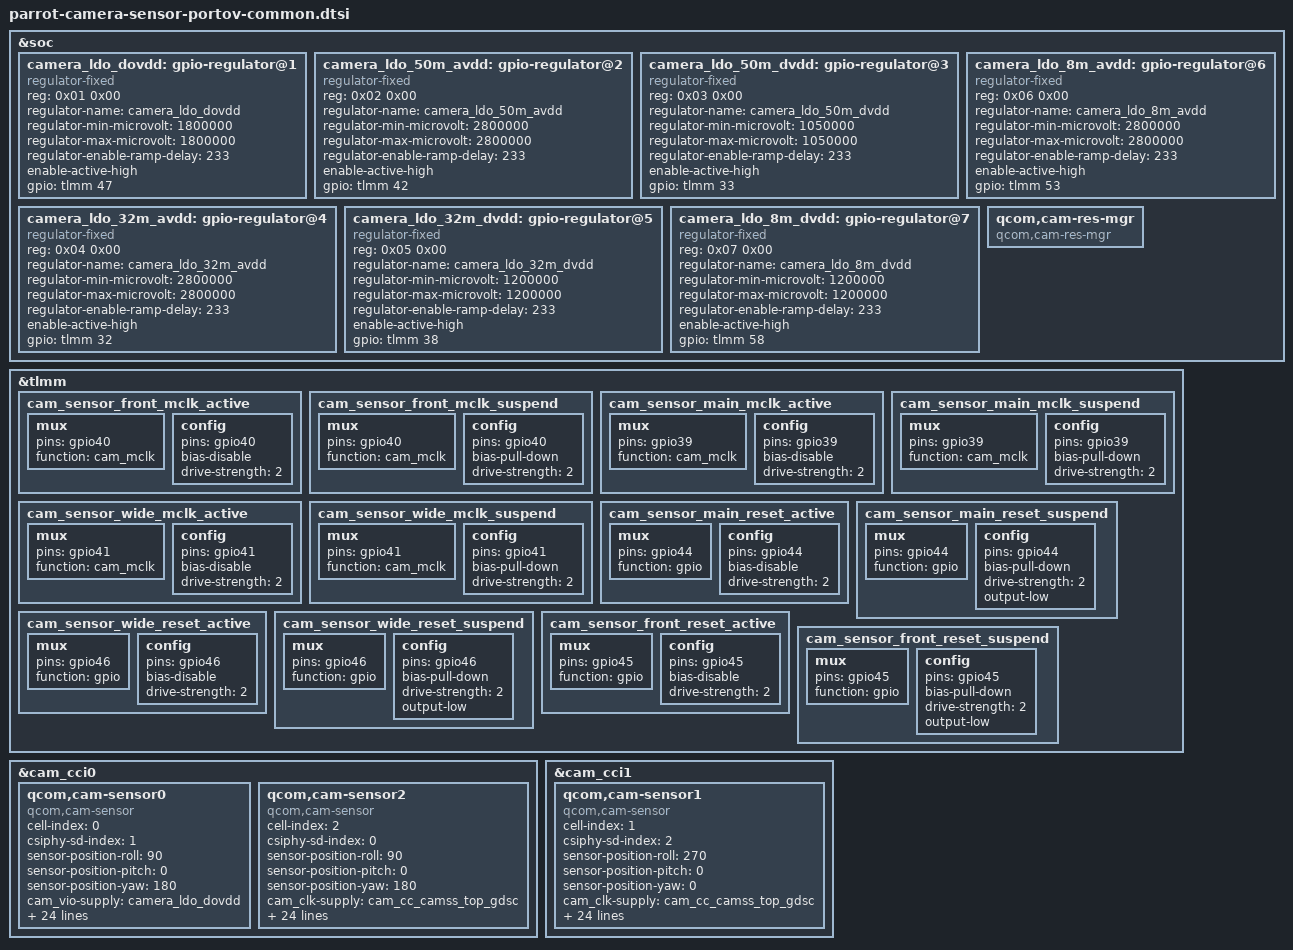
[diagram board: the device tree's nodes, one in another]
/*
   This base is original from "cape-camera-sensor-bronco-common.dtsi"
*/
#include <dt-bindings/clock/qcom,camcc-parrot.h>
#include <dt-bindings/msm-camera.h>

&soc {
	/* imx882 afvdd */
	/*camera_ldo_50m_afvdd: gpio-regulator@0 {
		compatible = "regulator-fixed";
		reg = <0x00 0x00>;
		regulator-name = "camera_ldo_50m_afvdd";
		regulator-min-microvolt = <2800000>;
		regulator-max-microvolt = <2800000>;
		regulator-enable-ramp-delay = <233>;
		enable-active-high;
		gpio = <&tlmm 31 0>;
	};*/

	camera_ldo_dovdd: gpio-regulator@1 {
		compatible = "regulator-fixed";
		reg = <0x01 0x00>;
		regulator-name = "camera_ldo_dovdd";
		regulator-min-microvolt = <1800000>;
		regulator-max-microvolt = <1800000>;
		regulator-enable-ramp-delay = <233>;
		enable-active-high;
		gpio = <&tlmm 47 0>;
	};

	/* imx882 avdd */
	camera_ldo_50m_avdd: gpio-regulator@2 {
		compatible = "regulator-fixed";
		reg = <0x02 0x00>;
		regulator-name = "camera_ldo_50m_avdd";
		regulator-min-microvolt = <2800000>;
		regulator-max-microvolt = <2800000>;
		regulator-enable-ramp-delay = <233>;
		enable-active-high;
		gpio = <&tlmm 42 0>;
	};
	/* imx882 dvdd */
	camera_ldo_50m_dvdd: gpio-regulator@3 {
		compatible = "regulator-fixed";
		reg = <0x03 0x00>;
		regulator-name = "camera_ldo_50m_dvdd";
		regulator-min-microvolt = <1050000>;
		regulator-max-microvolt = <1050000>;
		regulator-enable-ramp-delay = <233>;
		enable-active-high;
		gpio = <&tlmm 33 0>;
	};
	/* gc32e1 avdd */
	camera_ldo_32m_avdd: gpio-regulator@4 {
		compatible = "regulator-fixed";
		reg = <0x04 0x00>;
		regulator-name = "camera_ldo_32m_avdd";
		regulator-min-microvolt = <2800000>;
		regulator-max-microvolt = <2800000>;
		regulator-enable-ramp-delay = <233>;
		enable-active-high;
		gpio = <&tlmm 32 0>;
	};
	/* gc32e1 dvdd */
	camera_ldo_32m_dvdd: gpio-regulator@5 {
		compatible = "regulator-fixed";
		reg = <0x05 0x00>;
		regulator-name = "camera_ldo_32m_dvdd";
		regulator-min-microvolt = <1200000>;
		regulator-max-microvolt = <1200000>;
		regulator-enable-ramp-delay = <233>;
		enable-active-high;
		gpio = <&tlmm 38 0>;
	};
	/* sc820cs/gc08a8 avdd */
	camera_ldo_8m_avdd: gpio-regulator@6 {
		compatible = "regulator-fixed";
		reg = <0x06 0x00>;
		regulator-name = "camera_ldo_8m_avdd";
		regulator-min-microvolt = <2800000>;
		regulator-max-microvolt = <2800000>;
		regulator-enable-ramp-delay = <233>;
		enable-active-high;
		gpio = <&tlmm 53 0>;
	};
	/* sc820cs/gc08a8 dvdd */
	camera_ldo_8m_dvdd: gpio-regulator@7 {
		compatible = "regulator-fixed";
		reg = <0x07 0x00>;
		regulator-name = "camera_ldo_8m_dvdd";
		regulator-min-microvolt = <1200000>;
		regulator-max-microvolt = <1200000>;
		regulator-enable-ramp-delay = <233>;
		enable-active-high;
		gpio = <&tlmm 58 0>;
	};

        /*led_flash_rear: qcom,camera-flash@1 {
		cell-index = <1>;
		compatible = "qcom,camera-flash";
		flash-source = <&pm6150l_flash0 &pm6150l_flash1>;
		torch-source = <&pm6150l_torch0 &pm6150l_torch1>;
		switch-source = <&pm6150l_switch2>;
		status = "ok";
	};*/

	qcom,cam-res-mgr {
		compatible = "qcom,cam-res-mgr";
		status = "ok";
	};
};

&tlmm {
        cam_sensor_front_mclk_active: cam_sensor_front_mclk_active {
		mux {
			pins = "gpio40";
			function = "cam_mclk";
		};

		config {
			pins = "gpio40";
			bias-disable;
			drive-strength = <2>;
		};
	};

	cam_sensor_front_mclk_suspend: cam_sensor_front_mclk_suspend {
		mux {
			pins = "gpio40";
			function = "cam_mclk";
		};

		config {
			pins = "gpio40";
			bias-pull-down;
			drive-strength = <2>;
		};
	};

	cam_sensor_main_mclk_active: cam_sensor_main_mclk_active {
		mux {
			pins = "gpio39";
			function = "cam_mclk";
		};

		config {
			pins = "gpio39";
			bias-disable; /* No PULL */
			drive-strength = <2>; /* 2 MA */
		};
	};

	cam_sensor_main_mclk_suspend: cam_sensor_main_mclk_suspend {
		mux {
			pins = "gpio39";
			function = "cam_mclk";
		};

		config {
			pins = "gpio39";
			bias-pull-down; /* PULL DOWN */
			drive-strength = <2>; /* 2 MA */
		};
	};

	cam_sensor_wide_mclk_active: cam_sensor_wide_mclk_active {
		mux {
			pins = "gpio41";
			function = "cam_mclk";
		};

		config {
			pins = "gpio41";
			bias-disable; /* No PULL */
			drive-strength = <2>;
		};
	};

	cam_sensor_wide_mclk_suspend: cam_sensor_wide_mclk_suspend {
		mux {
			pins = "gpio41";
			function = "cam_mclk";
		};

		config {
			pins = "gpio41";
			bias-pull-down; /* PULL DOWN */
			drive-strength = <2>;
		};
	};
	cam_sensor_main_reset_active: cam_sensor_main_reset_active {
		mux {
			pins = "gpio44";
			function = "gpio";
		};

		config {
			pins = "gpio44";
			bias-disable; /* No PULL */
			drive-strength = <2>; /* 2 MA */
		};
	};

	cam_sensor_main_reset_suspend: cam_sensor_main_reset_suspend {
		mux {
			pins = "gpio44";
			function = "gpio";
		};

		config {
			pins = "gpio44";
			bias-pull-down; /* PULL DOWN */
			drive-strength = <2>; /* 2 MA */
			output-low;
		};
	};
	cam_sensor_wide_reset_active: cam_sensor_wide_reset_active {
		mux {
			pins = "gpio46";
			function = "gpio";
		};

		config {
			pins = "gpio46";
			bias-disable; /* No PULL */
			drive-strength = <2>; /* 2 MA */
		};
	};

	cam_sensor_wide_reset_suspend: cam_sensor_wide_reset_suspend {
		mux {
			pins = "gpio46";
			function = "gpio";
		};

		config {
			pins = "gpio46";
			bias-pull-down; /* PULL DOWN */
			drive-strength = <2>; /* 2 MA */
			output-low;
		};
	};
	cam_sensor_front_reset_active: cam_sensor_front_reset_active {
		mux {
			pins = "gpio45";
			function = "gpio";
		};

		config {
			pins = "gpio45";
			bias-disable;
			drive-strength = <2>;
		};
	};

	cam_sensor_front_reset_suspend: cam_sensor_front_reset_suspend {
		mux {
			pins = "gpio45";
			function = "gpio";
		};

		config {
			pins = "gpio45";
			bias-pull-down;
			drive-strength = <2>;
			output-low;
		};
	};
};

&cam_cci0 {
	/*actuator_rear_main:qcom,actuator0{
		cell-index = <0>;
		compatible = "qcom,actuator";
		cci-master = <CCI_MASTER_1>;
		cam_vaf-supply = <&camera_ldo_50m_afvdd>;
		regulator-names = "cam_vaf";
		rgltr-cntrl-support;
		rgltr-min-voltage = <2800000>;
		rgltr-max-voltage = <2800000>;
		rgltr-load-current = <0>;
	};*/

	/* Rear imx882 */
	qcom,cam-sensor0 {
		cell-index = <0>;
		compatible = "qcom,cam-sensor";
		csiphy-sd-index = <1>;
		sensor-position-roll = <90>;
		sensor-position-pitch = <0>;
		sensor-position-yaw = <180>;
		//actuator-src = <&actuator_rear_main>;
		//led-flash-src = <&led_flash_rear>;
		/* eeprom-src = <&eeprom_main>; */
		cam_vio-supply = <&camera_ldo_dovdd>;
		cam_vana-supply = <&camera_ldo_50m_avdd>;
		cam_vdig-supply = <&camera_ldo_50m_dvdd>;
		cam_clk-supply = <&cam_cc_camss_top_gdsc>;
		regulator-names = "cam_vio", "cam_vdig", "cam_vana", "cam_clk";
		rgltr-cntrl-support;
		rgltr-min-voltage = <1800000 1050000 2800000 0>;
		rgltr-max-voltage = <1800000 1050000 2800000 0>;
		rgltr-load-current = <120000 105000 80000 0>;
		gpio-no-mux = <0>;
		pinctrl-names = "cam_default", "cam_suspend";
 		pinctrl-0 = <&cam_sensor_main_mclk_active
 				     &cam_sensor_main_reset_active>;
 		pinctrl-1 = <&cam_sensor_main_mclk_suspend
 				     &cam_sensor_main_reset_suspend>;
		gpios = <&tlmm 39 0>,
			    <&tlmm 44 0>;
		gpio-reset = <1>;
		gpio-req-tbl-num = <0 1>;
		gpio-req-tbl-flags = <1 0>;
		gpio-req-tbl-label = "CAMIF_MCLK0",
					         "CAM_RESET0";
		sensor-mode = <0>;
		cci-master = <CCI_MASTER_1>;
		status = "ok";
		clocks = <&camcc CAM_CC_MCLK0_CLK>;
		clock-names = "cam_clk";
		clock-cntl-level = "nominal";
		clock-rates = <24000000>;
	};

    /*Rear Aux sc820 gc08a8*/
	qcom,cam-sensor2 {
		cell-index = <2>;
		compatible = "qcom,cam-sensor";
		csiphy-sd-index = <0>;
		sensor-position-roll = <90>;
		sensor-position-pitch = <0>;
		sensor-position-yaw = <180>;
		cam_clk-supply = <&cam_cc_camss_top_gdsc>;
		//actuator-src = <&actuator_rear>;
		//led-flash-src = <&led_flash_rear>;
		//eeprom-src = <&eeprom_rear>;
		cam_vio-supply = <&camera_ldo_dovdd>;
		cam_vana-supply = <&camera_ldo_8m_avdd>;
		cam_vdig-supply = <&camera_ldo_8m_dvdd>;
		regulator-names = "cam_vio", "cam_vana", "cam_vdig",
			"cam_clk";
		rgltr-cntrl-support;
		rgltr-min-voltage = <1800000 2800000 1200000 0>;
		rgltr-max-voltage = <1800000 2800000 1200000 0>;
		rgltr-load-current = <120000 80000 1200000 0>;
		gpio-no-mux = <0>;
		pinctrl-names = "cam_default", "cam_suspend";
		pinctrl-0 = <&cam_sensor_wide_mclk_active
			&cam_sensor_wide_reset_active>;
		pinctrl-1 = <&cam_sensor_wide_mclk_suspend
			&cam_sensor_wide_reset_suspend>;
		gpios = <&tlmm 41 0>,
			<&tlmm 46 0>;
		gpio-reset = <1>;
		gpio-req-tbl-num = <0 1>;
		gpio-req-tbl-flags = <1 0>;
		gpio-req-tbl-label = "CAMIF_MCLK2",
			"CAM_RESET2";
		sensor-mode = <0>;
		cci-master = <CCI_MASTER_0>;
		status = "ok";
		clocks = <&camcc CAM_CC_MCLK2_CLK>;
		clock-names = "cam_clk";
		clock-cntl-level = "nominal";
		clock-rates = <24000000>;
	};
};

&cam_cci1 {
	qcom,cam-sensor1 {
		cell-index = <1>;
		compatible = "qcom,cam-sensor";
		csiphy-sd-index = <2>;
		sensor-position-roll = <270>;
		sensor-position-pitch = <0>;
		sensor-position-yaw = <0>;
		cam_clk-supply = <&cam_cc_camss_top_gdsc>;
		cam_vio-supply = <&camera_ldo_dovdd>;
		cam_vana-supply = <&camera_ldo_32m_avdd>;
		cam_vdig-supply = <&camera_ldo_32m_dvdd>;
		regulator-names = "cam_vio", "cam_vana", "cam_vdig",
			"cam_clk";
		rgltr-cntrl-support;
		rgltr-min-voltage = <1800000 2800000 1200000 0>;
		rgltr-max-voltage = <1800000 2800000 1200000 0>;
		rgltr-load-current = <120000 80000 1200000 0>;
		gpio-no-mux = <0>;
		pinctrl-names = "cam_default", "cam_suspend";
		pinctrl-0 = <&cam_sensor_front_mclk_active
			&cam_sensor_front_reset_active>;
		pinctrl-1 = <&cam_sensor_front_mclk_suspend
			&cam_sensor_front_reset_suspend>;
		gpios = <&tlmm 40 0>,
			<&tlmm 45 0>;
		gpio-reset = <1>;
		gpio-req-tbl-num = <0 1>;
		gpio-req-tbl-flags = <1 0>;
		gpio-req-tbl-label = "CAMIF_MCLK1",
			"CAM_RESET1";
		sensor-mode = <0>;
		cci-master = <CCI_MASTER_1>;
		status = "ok";
		clocks = <&camcc CAM_CC_MCLK1_CLK>;
		clock-names = "cam_clk";
		clock-cntl-level = "nominal";
		clock-rates = <24000000>;
	};
};
